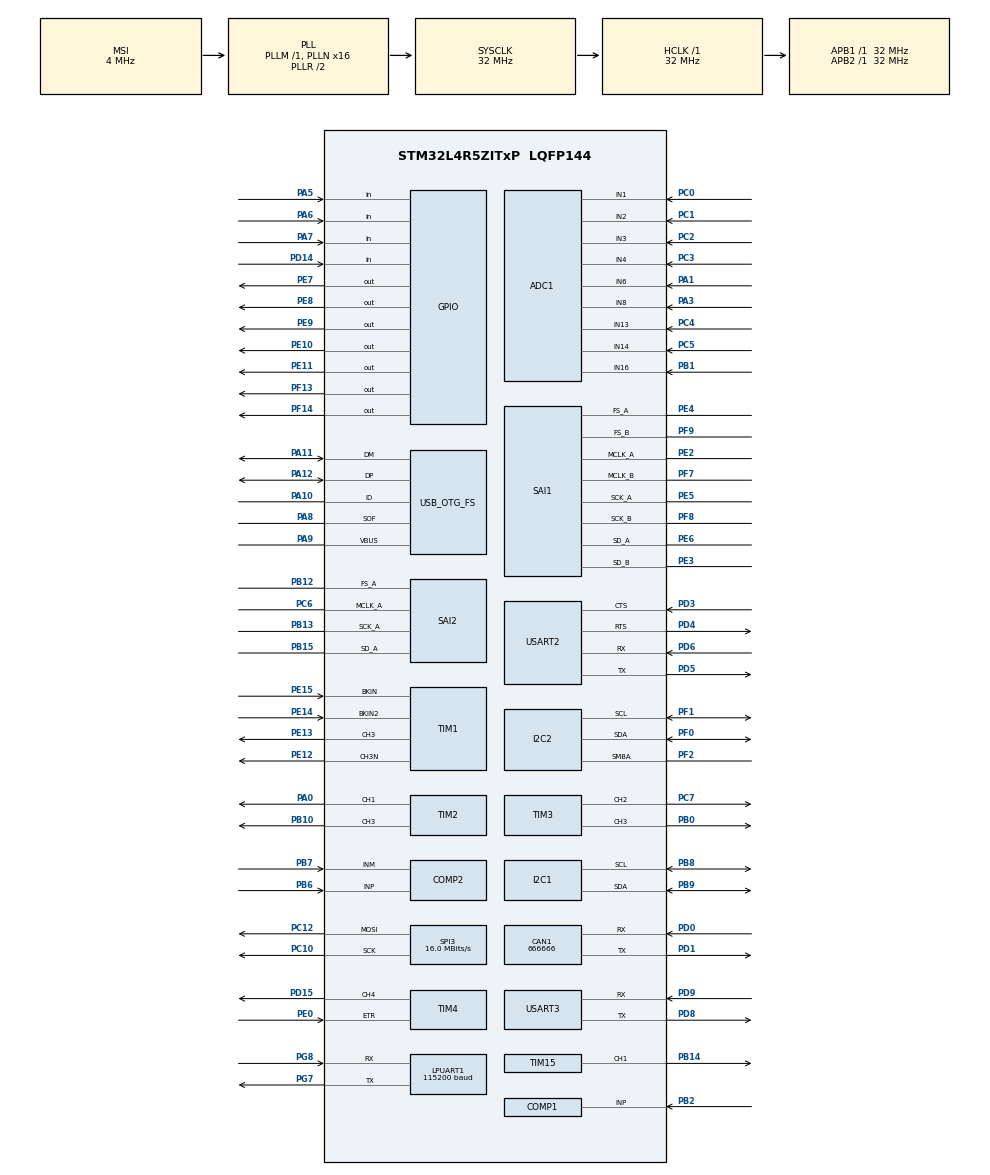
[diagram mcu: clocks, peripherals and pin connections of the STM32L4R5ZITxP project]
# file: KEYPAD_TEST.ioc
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ADC1.Channel-0\#ChannelRegularConversion=ADC_CHANNEL_1
ADC1.NbrOfConversionFlag=1
ADC1.OffsetNumber-0\#ChannelRegularConversion=ADC_OFFSET_NONE
ADC1.Rank-0\#ChannelRegularConversion=1
ADC1.SamplingTime-0\#ChannelRegularConversion=ADC_SAMPLETIME_2CYCLES_5
ADC1.master=1
CAN1.CalculateBaudRate=666666
CAN1.CalculateTimeBit=1500
CAN1.CalculateTimeQuantum=500.0
I2C1.Timeout=0x00008186
I2C1.Timing=0x00707CBB
I2C2.Timeout=0x00008186
I2C2.Timing=0x00707CBB
LPUART1.BaudRate=115200
LPUART1.WordLength=UART_WORDLENGTH_8B
Mcu.Family=STM32L4
Mcu.Name=STM32L4R5ZITxP
Mcu.Package=LQFP144
NVIC.PriorityGroup=NVIC_PRIORITYGROUP_4
PA0.Signal=S_TIM2_CH1
PA1.Signal=ADCx_IN6
PA10.Mode=OTG/Dual_Role_Device
PA10.Signal=USB_OTG_FS_ID
PA11.Mode=OTG/Dual_Role_Device
PA11.Signal=USB_OTG_FS_DM
PA12.Mode=OTG/Dual_Role_Device
PA12.Signal=USB_OTG_FS_DP
PA13\ (JTMS/SWDIO).Mode=Serial_Wire
PA13\ (JTMS/SWDIO).Signal=SYS_JTMS-SWDIO
PA14\ (JTCK/SWCLK).Mode=Serial_Wire
PA14\ (JTCK/SWCLK).Signal=SYS_JTCK-SWCLK
PA3.Signal=ADCx_IN8
PA4.Signal=SPI1_NSS
PA5.GPIO_PuPd=GPIO_PULLUP
PA5.Signal=GPIO_Input
PA6.GPIO_PuPd=GPIO_PULLUP
PA6.Signal=GPIO_Input
PA7.GPIO_PuPd=GPIO_PULLUP
PA7.Signal=GPIO_Input
PA8.Mode=Activate_SOF_FS
PA8.Signal=USB_OTG_FS_SOF
PA9.Mode=Activate_VBUS
PA9.Signal=USB_OTG_FS_VBUS
PB0.Signal=S_TIM3_CH3
PB1.Signal=ADCx_IN16
PB10.Signal=S_TIM2_CH3
PB12.Mode=SAI_A_MasterWithClock
PB12.Signal=SAI2_FS_A
PB13.Mode=SAI_A_MasterWithClock
PB13.Signal=SAI2_SCK_A
PB14.Signal=S_TIM15_CH1
PB15.Mode=SAI_A_MasterWithClock
PB15.Signal=SAI2_SD_A
PB2.Mode=INP
PB2.Signal=COMP1_INP
PB6.Mode=INP
PB6.Signal=COMP2_INP
PB7.Mode=INM
PB7.Signal=COMP2_INM
PB8.GPIO_Pu=GPIO_PULLUP
PB8.Mode=SMBus-two-wire-Interface
PB8.Signal=I2C1_SCL
PB9.GPIO_Pu=GPIO_PULLUP
PB9.Mode=SMBus-two-wire-Interface
PB9.Signal=I2C1_SDA
PC0.Signal=ADCx_IN1
PC1.Signal=ADCx_IN2
PC10.Mode=TX_Only_Simplex_Unidirect_Master
PC10.Signal=SPI3_SCK
PC11.Signal=SPI3_MISO
PC12.Mode=TX_Only_Simplex_Unidirect_Master
PC12.Signal=SPI3_MOSI
PC13.Mode=SYS_WakeUp1
PC13.Signal=SYS_WKUP2
PC14-OSC32_IN\ (PC14).Mode=LSE-External-Oscillator
PC14-OSC32_IN\ (PC14).Signal=RCC_OSC32_IN
PC15-OSC32_OUT\ (PC15).Mode=LSE-External-Oscillator
PC15-OSC32_OUT\ (PC15).Signal=RCC_OSC32_OUT
PC2.Signal=ADCx_IN3
PC3.Signal=ADCx_IN4
PC4.Signal=ADCx_IN13
PC5.Signal=ADCx_IN14
PC6.Mode=SAI_A_MasterWithClock
PC6.Signal=SAI2_MCLK_A
PC7.Signal=S_TIM3_CH2
PC8.Signal=SDMMC1_D0
PC9.Signal=SDMMC1_D1
PD0.Mode=CAN_Activate
PD0.Signal=CAN1_RX
PD1.Mode=CAN_Activate
PD1.Signal=CAN1_TX
PD14.GPIO_PuPd=GPIO_PULLUP
PD14.Signal=GPIO_Input
PD15.Signal=S_TIM4_CH4
PD2.Signal=SDMMC1_CMD
PD3.Mode=CTS_RTS
PD3.Signal=USART2_CTS
PD4.Mode=CTS_RTS
PD4.Signal=USART2_RTS
PD5.Mode=Asynchronous
PD5.Signal=USART2_TX
PD6.Mode=Asynchronous
PD6.Signal=USART2_RX
PD8.Mode=Asynchronous
PD8.Signal=USART3_TX
PD9.Mode=Asynchronous
PD9.Signal=USART3_RX
PE0.Signal=S_TIM4_ETR
PE10.GPIO_PuPd=GPIO_PULLUP
PE10.Signal=GPIO_Output
PE11.GPIO_ModeDefaultOutputPP=GPIO_MODE_OUTPUT_OD
PE11.GPIO_PuPd=GPIO_NOPULL
PE11.PinState=GPIO_PIN_RESET
PE11.Signal=GPIO_Output
PE12.Mode=PWM Generation3 CH3 CH3N
PE12.Signal=TIM1_CH3N
PE13.Signal=S_TIM1_CH3
PE14.Mode=Activate-Break-Input-2
PE14.Signal=TIM1_BKIN2
PE15.Mode=Activate-Break-Input
PE15.Signal=TIM1_BKIN
PE2.Mode=SAI_A_MasterWithClock
PE2.Signal=SAI1_MCLK_A
PE3.Mode=SAI_B_MasterWithClock
PE3.Signal=SAI1_SD_B
PE4.Mode=SAI_A_MasterWithClock
PE4.Signal=SAI1_FS_A
PE5.Mode=SAI_A_MasterWithClock
PE5.Signal=SAI1_SCK_A
PE6.Mode=SAI_A_MasterWithClock
PE6.Signal=SAI1_SD_A
PE7.GPIO_PuPd=GPIO_PULLUP
PE7.Signal=GPIO_Output
PE8.GPIO_PuPd=GPIO_PULLUP
PE8.Signal=GPIO_Output
PE9.GPIO_ModeDefaultOutputPP=GPIO_MODE_OUTPUT_OD
PE9.GPIO_PuPd=GPIO_NOPULL
PE9.PinState=GPIO_PIN_RESET
PE9.Signal=GPIO_Output
PF0.GPIO_Pu=GPIO_PULLUP
PF0.Mode=SMBus-Alert-mode
PF0.Signal=I2C2_SDA
PF1.GPIO_Pu=GPIO_PULLUP
PF1.Mode=SMBus-Alert-mode
PF1.Signal=I2C2_SCL
PF13.GPIO_ModeDefaultOutputPP=GPIO_MODE_OUTPUT_OD
PF13.GPIO_PuPd=GPIO_NOPULL
PF13.PinState=GPIO_PIN_RESET
PF13.Signal=GPIO_Output
PF14.GPIO_ModeDefaultOutputPP=GPIO_MODE_OUTPUT_OD
PF14.GPIO_PuPd=GPIO_NOPULL
PF14.PinState=GPIO_PIN_RESET
PF14.Signal=GPIO_Output
PF2.GPIO_Pu=GPIO_PULLUP
PF2.Mode=SMBus-Alert-mode
PF2.Signal=I2C2_SMBA
PF7.Mode=SAI_B_MasterWithClock
PF7.Signal=SAI1_MCLK_B
PF8.Mode=SAI_B_MasterWithClock
PF8.Signal=SAI1_SCK_B
PF9.Mode=SAI_B_MasterWithClock
PF9.Signal=SAI1_FS_B
PG7.Mode=Asynchronous
PG7.Signal=LPUART1_TX
PG8.Mode=Asynchronous
PG8.Signal=LPUART1_RX
PH0-OSC_IN\ (PH0).Mode=HSE-External-Oscillator
PH0-OSC_IN\ (PH0).Signal=RCC_OSC_IN
PH1-OSC_OUT\ (PH1).Mode=HSE-External-Oscillator
PH1-OSC_OUT\ (PH1).Signal=RCC_OSC_OUT
ProjectManager.HeapSize=0x200
ProjectManager.StackSize=0x400
ProjectManager.TargetToolchain=STM32CubeIDE
RCC.ADCFreq_Value=48000000
RCC.AHBFreq_Value=32000000
RCC.APB1Freq_Value=32000000
RCC.APB1TimFreq_Value=32000000
RCC.APB2Freq_Value=32000000
RCC.APB2TimFreq_Value=32000000
RCC.CortexFreq_Value=32000000
RCC.HCLKFreq_Value=32000000
RCC.HSE_VALUE=8000000
RCC.HSI48_VALUE=48000000
RCC.HSI_VALUE=16000000
RCC.MSI_VALUE=4000000
RCC.PLLN=16
RCC.PLLSAI1N=24
RCC.SYSCLKFreq_VALUE=32000000
RCC.SYSCLKSource=RCC_SYSCLKSOURCE_PLLCLK
RCC.USBFreq_Value=48000000
RCC.VCOOutputFreq_Value=64000000
SAI1.InitProtocol-SAI_A_MasterWithClock=Enable
SAI1.Instance-SAI_A_MasterWithClock=SAI$Index_Block_A
SAI1.Instance-SAI_B_MasterWithClock=SAI$Index_Block_B
SAI1.MClockEnable-SAI_A_MasterWithClock=SAI_MASTERCLOCK_ENABLE
SAI1.MClockEnable-SAI_B_MasterWithClock=SAI_MASTERCLOCK_ENABLE
SAI1.Synchro-SAI_A_MasterWithClock=SAI_ASYNCHRONOUS
SAI1.Synchro-SAI_B_MasterWithClock=SAI_ASYNCHRONOUS
SAI1.VirtualMode-SAI_A_MasterWithClock=VM_MASTER
SAI1.VirtualMode-SAI_B_MasterWithClock=VM_MASTER
SAI1.VirtualProtocol-SAI_A_BASIC=VM_BASIC_PROTOCOL
SAI2.Instance-SAI_A_MasterWithClock=SAI$Index_Block_A
SAI2.MClockEnable-SAI_A_MasterWithClock=SAI_MASTERCLOCK_ENABLE
SAI2.Synchro-SAI_A_MasterWithClock=SAI_ASYNCHRONOUS
SAI2.VirtualMode-SAI_A_MasterWithClock=VM_MASTER
SH.ADCx_IN1.0=ADC1_IN1,IN1-Single-Ended
SH.ADCx_IN13.0=ADC1_IN13,IN13-Single-Ended
SH.ADCx_IN14.0=ADC1_IN14,IN14-Single-Ended
SH.ADCx_IN16.0=ADC1_IN16,IN16-Single-Ended
SH.ADCx_IN2.0=ADC1_IN2,IN2-Single-Ended
SH.ADCx_IN3.0=ADC1_IN3,IN3-Single-Ended
SH.ADCx_IN4.0=ADC1_IN4,IN4-Single-Ended
SH.ADCx_IN6.0=ADC1_IN6,IN6-Single-Ended
SH.ADCx_IN8.0=ADC1_IN8,IN8-Single-Ended
SH.S_TIM15_CH1.0=TIM15_CH1,PWM Generation1 CH1
SH.S_TIM1_CH3.0=TIM1_CH3,PWM Generation3 CH3 CH3N
SH.S_TIM2_CH1.0=TIM2_CH1,PWM Generation1 CH1
SH.S_TIM2_CH3.0=TIM2_CH3,PWM Generation3 CH3
SH.S_TIM3_CH2.0=TIM3_CH2,PWM Generation2 CH2
SH.S_TIM3_CH3.0=TIM3_CH3,PWM Generation3 CH3
SH.S_TIM4_CH4.0=TIM4_CH4,PWM Generation4 CH4
SH.S_TIM4_ETR.0=TIM4_ETR,ETR-as-clearing-source
SPI3.CalculateBaudRate=16.0 MBits/s
SPI3.DataSize=SPI_DATASIZE_8BIT
SPI3.Direction=SPI_DIRECTION_2LINES
SPI3.Mode=SPI_MODE_MASTER
SPI3.VirtualType=VM_MASTER
TIM1.Channel-PWM\ Generation3\ CH3\ CH3N=TIM_CHANNEL_3
TIM15.Channel-PWM\ Generation1\ CH1=TIM_CHANNEL_1
TIM2.Channel-PWM\ Generation1\ CH1=TIM_CHANNEL_1
TIM2.Channel-PWM\ Generation3\ CH3=TIM_CHANNEL_3
TIM3.Channel-PWM\ Generation2\ CH2=TIM_CHANNEL_2
TIM3.Channel-PWM\ Generation3\ CH3=TIM_CHANNEL_3
TIM4.Channel-PWM\ Generation4\ CH4=TIM_CHANNEL_4
USART2.VirtualMode-Asynchronous=VM_ASYNC
USART3.VirtualMode-Asynchronous=VM_ASYNC
VP_COMP1_VS_VREFINT.Mode=VREFINT
VP_SAI1_VP_$IpInstance_SAIA_SAI_BASIC.Mode=SAI_A_BASIC
board=NUCLEO-L4R5ZI-P

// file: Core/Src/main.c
/* USER CODE BEGIN Header */
/**
 ******************************************************************************
 * @file           : main.c
 * @brief          : Main program body
 ******************************************************************************
 * @attention
 *
 * Copyright (c) 2024 STMicroelectronics.
 * All rights reserved.
 *
 * This software is licensed under terms that can be found in the LICENSE file
 * in the root directory of this software component.
 * If no LICENSE file comes with this software, it is provided AS-IS.
 *
 ******************************************************************************
 */
/* USER CODE END Header */
#include "main.h"

ADC_HandleTypeDef hadc1;

CAN_HandleTypeDef hcan1;

COMP_HandleTypeDef hcomp1;
COMP_HandleTypeDef hcomp2;

SMBUS_HandleTypeDef hsmbus1;
SMBUS_HandleTypeDef hsmbus2;

UART_HandleTypeDef hlpuart1;
UART_HandleTypeDef huart2;
UART_HandleTypeDef huart3;

SAI_HandleTypeDef hsai_BlockB1;
SAI_HandleTypeDef hsai_BlockA1;
SAI_HandleTypeDef hsai_BlockA2;

SPI_HandleTypeDef hspi3;

TIM_HandleTypeDef htim1;
TIM_HandleTypeDef htim2;
TIM_HandleTypeDef htim3;
TIM_HandleTypeDef htim4;
TIM_HandleTypeDef htim15;

/* USER CODE BEGIN PV */
// Defining dimensions of LCD display
#define LCD_WIDTH 240
#define LCD_HEIGHT 320

// Commands to control SPI display
// Specifically the ST7789 driver
typedef enum {
  CMD_MADCTL_MY = 0x80,
  CMD_MADCTL_MX = 0x40,
  CMD_MADCTL_MV = 0x20,
  CMD_MADCTL_ML = 0x10,
  CMD_MADCTL_RGB = 0x00,
  CMD_MADCTL_BGR = 0x08,
  CMD_MADCTL_MH = 0x04,
  CMD_NOP = 0x00,
  CMD_SWRESET = 0x01,
  CMD_RDDID = 0x04,
  CMD_RDDST = 0x09,
  CMD_SLPIN = 0x10,
  CMD_SLPOUT = 0x11,
  CMD_PTLON = 0x12,
  CMD_NORON = 0x13,
  CMD_INVOFF = 0x20,
  CMD_INVON = 0x21,
  CMD_GAMSET = 0x26,
  CMD_DISPOFF = 0x28,
  CMD_DISPON = 0x29,
  CMD_CASET = 0x2A,
  CMD_RASET = 0x2B,
  CMD_RAMWR = 0x2C,
  CMD_RAMRD = 0x2E,
  CMD_PTLAR = 0x30,
  CMD_MADCTL = 0x36,
  CMD_IDMOFF = 0x38,
  CMD_IDMON = 0x39,
  CMD_COLMOD = 0x3A,
  CMD_RAMCTRL = 0xB0,
  CMD_FRMCTR1 = 0xB1,
  CMD_RGBCTRL = 0xB1,
  CMD_FRMCTR2 = 0xB2,
  CMD_PORCTRL = 0xB2,
  CMD_FRMCTR3 = 0xB3,
  CMD_FRCTRL1 = 0xB3,
  CMD_INVCTR = 0xB4,
  CMD_PARCTRL = 0xB5,
  CMD_DISSET5 = 0xB6,
  CMD_GCTRL = 0xB7,
  CMD_VCOMS = 0xBB,
  CMD_PWCTR1 = 0xC0,
  CMD_LCMCTRL = 0xC0,
  CMD_PWCTR2 = 0xC1,
  CMD_IDSET = 0xC1,
  CMD_PWCTR3 = 0xC2,
  CMD_VDVVRHEN = 0xC2,
  CMD_PWCTR4 = 0xC3,
  CMD_VRHS = 0xC3,
  CMD_PWCTR5 = 0xC4,
  CMD_VDVS = 0xC4,
  CMD_VMCTR1 = 0xC5,
  CMD_VCMOFSET = 0xC5,
  CMD_FRCTRL2 = 0xC6,
  CMD_PWCTRL1 = 0xD0,
  CMD_RDID1 = 0xDA,
  CMD_RDID2 = 0xDB,
  CMD_RDID3 = 0xDC,
  CMD_RDID4 = 0xDD,
  CMD_PWCTR6 = 0xFC,
  CMD_GMCTRP1 = 0xE0,
  CMD_GMCTRN1 = 0xE1,
  CMD_COLOR_MODE_16bit = 0x55,
  CMD_COLOR_MODE_18bit = 0x66,
} lcd_cmds;

// I'm still not sure how this defines rotation TBH
#define LCD_ROTATION_CMD (CMD_MADCTL_MX | CMD_MADCTL_MY | CMD_MADCTL_RGB)

// Commands to be run during initialization
const uint8_t init_cmd[] = {
    0,  CMD_SLPOUT,
    1,  CMD_COLMOD,  CMD_COLOR_MODE_16bit,
    5,  CMD_PORCTRL, 0x0C, 0x0C, 0x00, 0x33, 0x33,   // Standard porch
  //5,  CMD_PORCTRL, 0x01, 0x01, 0x00, 0x11, 0x11,   // Minimum porch (7% faster screen refresh rate)
    1,  CMD_GCTRL,   0x35,                           // Gate Control, Default value
    1,  CMD_VCOMS,   0x19,                           // VCOM setting 0.725v (default 0.75v for 0x20)
    1,  CMD_LCMCTRL, 0X2C,                           // LCMCTRL, Default value
    1,  CMD_VDVVRHEN,0x01,                           // VDV and VRH command Enable, Default value
    1,  CMD_VRHS,    0x12,                           // VRH set, +-4.45v (default +-4.1v for 0x0B)
    1,  CMD_VDVS,    0x20,                           // VDV set, Default value
    1,  CMD_FRCTRL2, 0x0F,                           // Frame rate control in normal mode, Default refresh rate (60Hz)
  //1,  CMD_FRCTRL2, 0x01,                           // Frame rate control in normal mode, Max refresh rate (111Hz)
    2,  CMD_PWCTRL1, 0xA4, 0xA1,
    1,  CMD_MADCTL,  LCD_ROTATION_CMD,
    14, CMD_GMCTRP1, 0xD0, 0x04, 0x0D, 0x11, 0x13, 0x2B, 0x3F, 0x54, 0x4C, 0x18, 0x0D, 0x0B, 0x1F, 0x23,
    14, CMD_GMCTRN1, 0xD0, 0x04, 0x0C, 0x11, 0x13, 0x2C, 0x3F, 0x44, 0x51, 0x2F, 0x1F, 0x1F, 0x20, 0x23,
    0,  CMD_INVON,
    0,  CMD_NORON
};

/* USER CODE END PV */

void SystemClock_Config(void);
void PeriphCommonClock_Config(void);
static void MX_GPIO_Init(void);
static void MX_ADC1_Init(void);
static void MX_CAN1_Init(void);
static void MX_COMP1_Init(void);
static void MX_COMP2_Init(void);
static void MX_I2C1_SMBUS_Init(void);
static void MX_I2C2_SMBUS_Init(void);
static void MX_LPUART1_UART_Init(void);
static void MX_USART2_UART_Init(void);
static void MX_USART3_UART_Init(void);
static void MX_SAI1_Init(void);
static void MX_SAI2_Init(void);
static void MX_SPI3_Init(void);
static void MX_TIM1_Init(void);
static void MX_TIM2_Init(void);
static void MX_TIM3_Init(void);
static void MX_TIM4_Init(void);
static void MX_TIM15_Init(void);
static void MX_USB_OTG_FS_USB_Init(void);

/* USER CODE BEGIN 0 */
// #define SPI3_ADDR 0x40003C00
// #define SPI_CR1_OFFSET 0x00
// #define SPI_CR2_OFFSET 0x04

// Send a command to the display
static void LCD_WriteCommand(uint8_t *cmd, uint8_t argc) {
  //    setSPI_Size(mode_8bit);
  //    LCD_PIN(LCD_DC,RESET);
  HAL_GPIO_WritePin(GPIOE, GPIO_PIN_8, 0);   // DC
  HAL_GPIO_WritePin(GPIOE, GPIO_PIN_10, 0);  // CS

  HAL_SPI_Transmit(&hspi3, cmd, 1, HAL_MAX_DELAY);
  if (argc) {
    HAL_GPIO_WritePin(GPIOE, GPIO_PIN_8, 1);
    HAL_SPI_Transmit(&hspi3, (cmd + 1), argc, HAL_MAX_DELAY);
  }
  HAL_GPIO_WritePin(GPIOE, GPIO_PIN_10, 1);  // CS
}

// Power on display
void LCD_setPower(uint8_t power) {
  uint8_t cmd[] = {(power ? CMD_DISPON /* TEON */ : CMD_DISPOFF /* TEOFF */)};
  LCD_WriteCommand(cmd, sizeof(cmd) - 1);
}

// Initialize display
void LCD_init(void) {
  HAL_GPIO_WritePin(GPIOE, GPIO_PIN_10, 1);  // CS
  HAL_GPIO_WritePin(GPIOE, GPIO_PIN_7, 0);   // RST
  HAL_Delay(1);
  HAL_GPIO_WritePin(GPIOE, GPIO_PIN_7, 1);  // RST
  HAL_Delay(200);
  // Iterate through initialization commands defined previousy
  for (uint16_t i = 0; i < sizeof(init_cmd);) {
    LCD_WriteCommand((uint8_t *)&init_cmd[i + 1], init_cmd[i]);
    i += init_cmd[i] + 2;
  }
  // Power on display once initialized
  LCD_setPower(ENABLE);
}

static void LCD_SetAddressWindow(int16_t x0, int16_t y0, int16_t x1,
                                 int16_t y1) {
  int16_t x_start = x0 /*+ LCD_X_SHIFT*/, x_end = x1 /*+ LCD_X_SHIFT*/;
  int16_t y_start = y0 /*+ LCD_Y_SHIFT*/, y_end = y1 /*+ LCD_Y_SHIFT*/;

  /* Column Address set */
  {
    uint8_t cmd[] = {CMD_CASET, x_start >> 8, x_start & 0xFF, x_end >> 8,
                     x_end & 0xFF};
    LCD_WriteCommand(cmd, sizeof(cmd) - 1);
  }
  /* Row Address set */
  {
    uint8_t cmd[] = {CMD_RASET, y_start >> 8, y_start & 0xFF, y_end >> 8,
                     y_end & 0xFF};
    LCD_WriteCommand(cmd, sizeof(cmd) - 1);
  }
  {
    /* Write to RAM */
    uint8_t cmd[] = {CMD_RAMWR};
    LCD_WriteCommand(cmd, sizeof(cmd) - 1);
  }
}

void LCD_DrawPixel(int16_t x, int16_t y, uint16_t color) {
  if ((x < 0) || (x > LCD_WIDTH - 1) || (y < 0) || (y > LCD_HEIGHT - 1)) return;

  uint8_t data[2] = {color >> 8, color & 0xFF};

  LCD_SetAddressWindow(x, y, x, y);

  HAL_GPIO_WritePin(GPIOE, GPIO_PIN_8, 1);  // DC

  HAL_GPIO_WritePin(GPIOE, GPIO_PIN_10, 0);  // CS

  HAL_SPI_Transmit(&hspi3, data, sizeof(data), HAL_MAX_DELAY);
  HAL_GPIO_WritePin(GPIOE, GPIO_PIN_10, 1);  // CS
}

/* USER CODE END 0 */

int main(void) {
  /* USER CODE BEGIN 1 */

  // SPI3 address 0x40003C00
  // SPI3_CR1 offset is 0x00
  // SPI3_CR2 offset is 0x04

  /* USER CODE END 1 */

  /* MCU Configuration--------------------------------------------------------*/

  /* Reset of all peripherals, Initializes the Flash interface and the Systick.
   */
  HAL_Init();

  /* Configure the system clock */
  SystemClock_Config();

  /* Configure the peripherals common clocks */
  PeriphCommonClock_Config();

  /* Initialize all configured peripherals */
  MX_GPIO_Init();
  MX_ADC1_Init();
  MX_CAN1_Init();
  MX_COMP1_Init();
  MX_COMP2_Init();
  MX_I2C1_SMBUS_Init();
  MX_I2C2_SMBUS_Init();
  MX_LPUART1_UART_Init();
  MX_USART2_UART_Init();
  MX_USART3_UART_Init();
  MX_SAI1_Init();
  MX_SAI2_Init();
  MX_SPI3_Init();
  MX_TIM1_Init();
  MX_TIM2_Init();
  MX_TIM3_Init();
  MX_TIM4_Init();
  MX_TIM15_Init();
  MX_USB_OTG_FS_USB_Init();
  /* USER CODE BEGIN 2 */

  //  struct ROW_RETURN{
  //	  int row1;
  //	  int row2;
  //	  int row3;
  //	  int row4;
  //  };

  /**
   * KEYPAD FUNCTIONS BELOW
  */
  int RowChecker() {
    // struct ROW_RETURN row_return;

    //	  	row_return.row1 = HAL_GPIO_ReadPin(GPIOA, GPIO_PIN_5) ==
    // GPIO_PIN_RESET; 	  	row_return.row2 =  HAL_GPIO_ReadPin(GPIOA,
    // GPIO_PIN_6) == GPIO_PIN_RESET; 	  	row_return.row3 =
    // HAL_GPIO_ReadPin(GPIOA, GPIO_PIN_7) == GPIO_PIN_RESET;
    // row_return.row4 = HAL_GPIO_ReadPin(GPIOD, GPIO_PIN_14) == GPIO_PIN_RESET;
    int val = 0;
    val = HAL_GPIO_ReadPin(GPIOA, GPIO_PIN_5) == GPIO_PIN_RESET ? 1 : val;
    val = HAL_GPIO_ReadPin(GPIOA, GPIO_PIN_6) == GPIO_PIN_RESET ? 2 : val;
    val = HAL_GPIO_ReadPin(GPIOA, GPIO_PIN_7) == GPIO_PIN_RESET ? 3 : val;
    val = HAL_GPIO_ReadPin(GPIOD, GPIO_PIN_14) == GPIO_PIN_RESET ? 4 : val;
    //	  	return row_return;
    return val;
  }

  //  struct ROW_RETURN Col1_Return;
  //  struct ROW_RETURN Col2_Return;
  //  struct ROW_RETURN Col3_Return;
  //  struct ROW_RETURN Col4_Return;
  int val = 0;
  HAL_GPIO_WritePin(GPIOE, GPIO_PIN_9, 1);
  HAL_GPIO_WritePin(GPIOF, GPIO_PIN_13, 1);
  HAL_GPIO_WritePin(GPIOE, GPIO_PIN_11, 1);
  HAL_GPIO_WritePin(GPIOF, GPIO_PIN_14, 1);
  uint8_t ASCII_Keypad_Lookup[4][4] = {{0x31, 0x32, 0x33, 0x41},
                                       {0x34, 0x35, 0x36, 0x42},
                                       {0x37, 0x38, 0x39, 0x43},
                                       {0x2A, 0x30, 0x23, 0x44}};
  const uint8_t max_digits = 5;
  uint8_t ASCII_Weight[max_digits];
  uint8_t weightCounter = 0;
  // uint8_t ASCII_Height [5];
  // uint8_t heightCounter = 0; implement later

  void KeyPadReturn(int row, int col) {
    if (row == 0) {
      return;
    }
    HAL_Delay(10);
    while (row == RowChecker()) {
    }
    HAL_Delay(10);
    uint8_t ASCII_Value = ASCII_Keypad_Lookup[row - 1][col - 1];
    // Check if '#' is pressed
    if (ASCII_Value == 0x23) {
      if (weightCounter == 0) {
        // If there is no value for weight, just return
        return;
      }
      // print the weight or height
      printf("End ASCII value: ");
      for (uint8_t i = 0; i < weightCounter; i++) {
        // print the values here
        printf("%x ", ASCII_Weight[i]);
      }
      printf("\n");
      weightCounter = 0;
      return;
    } else if (ASCII_Value == 0x2A || weightCounter == max_digits - 2) {
      // Reset if '*' is the input
      // Other if statement:
      // -2: there is a ++ at the end, and need a spot for #
      // Reset if max digits have been reached
      weightCounter = 0;
      return;
    }
    printf("ASCII value: %x\n", ASCII_Value);
    ASCII_Weight[weightCounter] = ASCII_Value;
    weightCounter++;
  }

  /**
   * DISPLAY FUNCTIONS BELOW
  */
  LCD_init();

  //  uint8_t data[2] = {0xffc0 >> 8, 0xffc0 & 0xFF};
  //
  //  uint8_t cmd[] = { CMD_CASET, 50 >> 8, 50 & 0xFF, 50 >> 8, 50 & 0xFF };
  //  HAL_SPI_Transmit(&hspi3, cmd, 1, HAL_MAX_DELAY);
  //  HAL_SPI_Transmit(&hspi3, data, sizeof(data), HAL_MAX_DELAY);

  // LOOPS below draw the message "Hi"
  for (int i = 0; i < 240; i++) {
    for (int j = 0; j < 320; j++) {
      LCD_DrawPixel(i, j, 0x0149);
    }
  }

  for (int j = 120; j < 240; j++) {
    LCD_DrawPixel(200, j, 0xffC0);
    LCD_DrawPixel(201, j, 0xffC0);
    LCD_DrawPixel(202, j, 0xffC0);
    LCD_DrawPixel(203, j, 0xffC0);
    LCD_DrawPixel(204, j, 0xffC0);
    LCD_DrawPixel(205, j, 0xffC0);
  }

  for (int j = 120; j < 240; j++) {
    LCD_DrawPixel(140, j, 0xffC0);
    LCD_DrawPixel(141, j, 0xffC0);
    LCD_DrawPixel(142, j, 0xffC0);
    LCD_DrawPixel(143, j, 0xffC0);
    LCD_DrawPixel(144, j, 0xffC0);
    LCD_DrawPixel(145, j, 0xffC0);
  }
  for (int i = 205; i > 144; i--) {
    LCD_DrawPixel(i, 180, 0xffC0);
    LCD_DrawPixel(i, 181, 0xffC0);
    LCD_DrawPixel(i, 182, 0xffC0);
    LCD_DrawPixel(i, 183, 0xffC0);
    LCD_DrawPixel(i, 184, 0xffC0);
    LCD_DrawPixel(i, 185, 0xffC0);
  }
  for (int j = 120; j < 200; j++) {
    LCD_DrawPixel(120, j, 0xffC0);
    LCD_DrawPixel(121, j, 0xffC0);
    LCD_DrawPixel(122, j, 0xffC0);
    LCD_DrawPixel(123, j, 0xffC0);
    LCD_DrawPixel(124, j, 0xffC0);
    LCD_DrawPixel(125, j, 0xffC0);
  }
  for (int j = 220; j < 226; j++) {
    LCD_DrawPixel(120, j, 0xffC0);
    LCD_DrawPixel(121, j, 0xffC0);
    LCD_DrawPixel(122, j, 0xffC0);
    LCD_DrawPixel(123, j, 0xffC0);
    LCD_DrawPixel(124, j, 0xffC0);
    LCD_DrawPixel(125, j, 0xffC0);
  }
  // End of "Hi" message

  /* USER CODE END 2 */

  /* Infinite loop */
  /* USER CODE BEGIN WHILE */
  while (1) {
    //	  LCD_DrawPixel(50, 50, 0x001f);
    //	  LCD_DrawPixel(100, 100, 0xffC0);
    //	  LCD_DrawPixel(100, 100, 0x001f);
    //	  LCD_DrawPixel(1, 1, 0xffC0);
    //	  LCD_DrawPixel(1, 1, 0x001f);
    HAL_Delay(500);
    // COMMENTING BELOW FOR DISPLAY TESTING
    //    HAL_GPIO_WritePin(GPIOF, GPIO_PIN_13, 0);
    //    val = RowChecker();
    //    KeyPadReturn(val, 4);
    //    HAL_GPIO_WritePin(GPIOF, GPIO_PIN_13, 1);
    //
    //    HAL_GPIO_WritePin(GPIOE, GPIO_PIN_9, 0);
    //    val = RowChecker();
    //    KeyPadReturn(val, 3);
    //    HAL_GPIO_WritePin(GPIOE, GPIO_PIN_9, 1);
    //
    //    HAL_GPIO_WritePin(GPIOE, GPIO_PIN_11, 0);
    //    val = RowChecker();
    //    KeyPadReturn(val, 2);
    //    HAL_GPIO_WritePin(GPIOE, GPIO_PIN_11, 1);
    //
    //    HAL_GPIO_WritePin(GPIOF, GPIO_PIN_14, 0);
    //    val = RowChecker();
    //    KeyPadReturn(val, 1);
    //    HAL_GPIO_WritePin(GPIOF, GPIO_PIN_14, 1);

    /* USER CODE END WHILE */

  }
}

void SystemClock_Config(void) {
  RCC_OscInitTypeDef RCC_OscInitStruct = {0};
  RCC_ClkInitTypeDef RCC_ClkInitStruct = {0};

  /** Configure the main internal regulator output voltage
   */
  if (HAL_PWREx_ControlVoltageScaling(PWR_REGULATOR_VOLTAGE_SCALE1) != HAL_OK) {
    Error_Handler();
  }

  /** Configure LSE Drive Capability
   */
  HAL_PWR_EnableBkUpAccess();
  __HAL_RCC_LSEDRIVE_CONFIG(RCC_LSEDRIVE_LOW);

  /** Initializes the RCC Oscillators according to the specified parameters
   * in the RCC_OscInitTypeDef structure.
   */
  RCC_OscInitStruct.OscillatorType =
      RCC_OSCILLATORTYPE_LSE | RCC_OSCILLATORTYPE_MSI;
  RCC_OscInitStruct.LSEState = RCC_LSE_ON;
  RCC_OscInitStruct.MSIState = RCC_MSI_ON;
  RCC_OscInitStruct.MSICalibrationValue = 0;
  RCC_OscInitStruct.MSIClockRange = RCC_MSIRANGE_6;
  RCC_OscInitStruct.PLL.PLLState = RCC_PLL_ON;
  RCC_OscInitStruct.PLL.PLLSource = RCC_PLLSOURCE_MSI;
  RCC_OscInitStruct.PLL.PLLM = 1;
  RCC_OscInitStruct.PLL.PLLN = 16;
  RCC_OscInitStruct.PLL.PLLP = RCC_PLLP_DIV2;
  RCC_OscInitStruct.PLL.PLLQ = RCC_PLLQ_DIV2;
  RCC_OscInitStruct.PLL.PLLR = RCC_PLLR_DIV2;
  if (HAL_RCC_OscConfig(&RCC_OscInitStruct) != HAL_OK) {
    Error_Handler();
  }

  /** Initializes the CPU, AHB and APB buses clocks
   */
  RCC_ClkInitStruct.ClockType = RCC_CLOCKTYPE_HCLK | RCC_CLOCKTYPE_SYSCLK |
                                RCC_CLOCKTYPE_PCLK1 | RCC_CLOCKTYPE_PCLK2;
  RCC_ClkInitStruct.SYSCLKSource = RCC_SYSCLKSOURCE_PLLCLK;
  RCC_ClkInitStruct.AHBCLKDivider = RCC_SYSCLK_DIV1;
  RCC_ClkInitStruct.APB1CLKDivider = RCC_HCLK_DIV1;
  RCC_ClkInitStruct.APB2CLKDivider = RCC_HCLK_DIV1;

  if (HAL_RCC_ClockConfig(&RCC_ClkInitStruct, FLASH_LATENCY_1) != HAL_OK) {
    Error_Handler();
  }

  /** Enable MSI Auto calibration
   */
  HAL_RCCEx_EnableMSIPLLMode();
}

void PeriphCommonClock_Config(void) {
  RCC_PeriphCLKInitTypeDef PeriphClkInit = {0};

  /** Initializes the peripherals clock
   */
  PeriphClkInit.PeriphClockSelection = RCC_PERIPHCLK_SAI1 | RCC_PERIPHCLK_SAI2 |
                                       RCC_PERIPHCLK_USB | RCC_PERIPHCLK_ADC;
  PeriphClkInit.Sai1ClockSelection = RCC_SAI1CLKSOURCE_PLLSAI1;
  PeriphClkInit.Sai2ClockSelection = RCC_SAI2CLKSOURCE_PLLSAI1;
  PeriphClkInit.AdcClockSelection = RCC_ADCCLKSOURCE_PLLSAI1;
  PeriphClkInit.UsbClockSelection = RCC_USBCLKSOURCE_PLLSAI1;
  PeriphClkInit.PLLSAI1.PLLSAI1Source = RCC_PLLSOURCE_MSI;
  PeriphClkInit.PLLSAI1.PLLSAI1M = 1;
  PeriphClkInit.PLLSAI1.PLLSAI1N = 24;
  PeriphClkInit.PLLSAI1.PLLSAI1P = RCC_PLLP_DIV2;
  PeriphClkInit.PLLSAI1.PLLSAI1Q = RCC_PLLQ_DIV2;
  PeriphClkInit.PLLSAI1.PLLSAI1R = RCC_PLLR_DIV2;
  PeriphClkInit.PLLSAI1.PLLSAI1ClockOut =
      RCC_PLLSAI1_SAI1CLK | RCC_PLLSAI1_48M2CLK | RCC_PLLSAI1_ADC1CLK;
  if (HAL_RCCEx_PeriphCLKConfig(&PeriphClkInit) != HAL_OK) {
    Error_Handler();
  }
}

static void MX_ADC1_Init(void) {

  ADC_ChannelConfTypeDef sConfig = {0};

  /** Common config
   */
  hadc1.Instance = ADC1;
  hadc1.Init.ClockPrescaler = ADC_CLOCK_ASYNC_DIV1;
  hadc1.Init.Resolution = ADC_RESOLUTION_12B;
  hadc1.Init.DataAlign = ADC_DATAALIGN_RIGHT;
  hadc1.Init.ScanConvMode = ADC_SCAN_DISABLE;
  hadc1.Init.EOCSelection = ADC_EOC_SINGLE_CONV;
  hadc1.Init.LowPowerAutoWait = DISABLE;
  hadc1.Init.ContinuousConvMode = DISABLE;
  hadc1.Init.NbrOfConversion = 1;
  hadc1.Init.DiscontinuousConvMode = DISABLE;
  hadc1.Init.ExternalTrigConv = ADC_SOFTWARE_START;
  hadc1.Init.ExternalTrigConvEdge = ADC_EXTERNALTRIGCONVEDGE_NONE;
  hadc1.Init.DMAContinuousRequests = DISABLE;
  hadc1.Init.Overrun = ADC_OVR_DATA_PRESERVED;
  hadc1.Init.OversamplingMode = DISABLE;
  if (HAL_ADC_Init(&hadc1) != HAL_OK) {
    Error_Handler();
  }

  /** Configure Regular Channel
   */
  sConfig.Channel = ADC_CHANNEL_1;
  sConfig.Rank = ADC_REGULAR_RANK_1;
  sConfig.SamplingTime = ADC_SAMPLETIME_2CYCLES_5;
  sConfig.SingleDiff = ADC_SINGLE_ENDED;
  sConfig.OffsetNumber = ADC_OFFSET_NONE;
  sConfig.Offset = 0;
  if (HAL_ADC_ConfigChannel(&hadc1, &sConfig) != HAL_OK) {
    Error_Handler();
  }
}

static void MX_CAN1_Init(void) {

  hcan1.Instance = CAN1;
  hcan1.Init.Prescaler = 16;
  hcan1.Init.Mode = CAN_MODE_NORMAL;
  hcan1.Init.SyncJumpWidth = CAN_SJW_1TQ;
  hcan1.Init.TimeSeg1 = CAN_BS1_1TQ;
  hcan1.Init.TimeSeg2 = CAN_BS2_1TQ;
  hcan1.Init.TimeTriggeredMode = DISABLE;
  hcan1.Init.AutoBusOff = DISABLE;
  hcan1.Init.AutoWakeUp = DISABLE;
  hcan1.Init.AutoRetransmission = DISABLE;
  hcan1.Init.ReceiveFifoLocked = DISABLE;
  hcan1.Init.TransmitFifoPriority = DISABLE;
  if (HAL_CAN_Init(&hcan1) != HAL_OK) {
    Error_Handler();
  }
}

static void MX_COMP1_Init(void) {

  hcomp1.Instance = COMP1;
  hcomp1.Init.InvertingInput = COMP_INPUT_MINUS_VREFINT;
  hcomp1.Init.NonInvertingInput = COMP_INPUT_PLUS_IO2;
  hcomp1.Init.OutputPol = COMP_OUTPUTPOL_NONINVERTED;
  hcomp1.Init.Hysteresis = COMP_HYSTERESIS_NONE;
  hcomp1.Init.BlankingSrce = COMP_BLANKINGSRC_NONE;
  hcomp1.Init.Mode = COMP_POWERMODE_HIGHSPEED;
  hcomp1.Init.WindowMode = COMP_WINDOWMODE_DISABLE;
  hcomp1.Init.TriggerMode = COMP_TRIGGERMODE_NONE;
  if (HAL_COMP_Init(&hcomp1) != HAL_OK) {
    Error_Handler();
  }
}

static void MX_COMP2_Init(void) {

  hcomp2.Instance = COMP2;
  hcomp2.Init.InvertingInput = COMP_INPUT_MINUS_IO2;
  hcomp2.Init.NonInvertingInput = COMP_INPUT_PLUS_IO2;
  hcomp2.Init.OutputPol = COMP_OUTPUTPOL_NONINVERTED;
  hcomp2.Init.Hysteresis = COMP_HYSTERESIS_NONE;
  hcomp2.Init.BlankingSrce = COMP_BLANKINGSRC_NONE;
  hcomp2.Init.Mode = COMP_POWERMODE_HIGHSPEED;
  hcomp2.Init.WindowMode = COMP_WINDOWMODE_DISABLE;
  hcomp2.Init.TriggerMode = COMP_TRIGGERMODE_NONE;
  if (HAL_COMP_Init(&hcomp2) != HAL_OK) {
    Error_Handler();
  }
}

static void MX_I2C1_SMBUS_Init(void) {

  hsmbus1.Instance = I2C1;
  hsmbus1.Init.Timing = 0x00707CBB;
  hsmbus1.Init.AnalogFilter = SMBUS_ANALOGFILTER_ENABLE;
  hsmbus1.Init.OwnAddress1 = 2;
  hsmbus1.Init.AddressingMode = SMBUS_ADDRESSINGMODE_7BIT;
  hsmbus1.Init.DualAddressMode = SMBUS_DUALADDRESS_DISABLE;
  hsmbus1.Init.OwnAddress2 = 0;
  hsmbus1.Init.OwnAddress2Masks = SMBUS_OA2_NOMASK;
  hsmbus1.Init.GeneralCallMode = SMBUS_GENERALCALL_DISABLE;
  hsmbus1.Init.NoStretchMode = SMBUS_NOSTRETCH_DISABLE;
  hsmbus1.Init.PacketErrorCheckMode = SMBUS_PEC_DISABLE;
  hsmbus1.Init.PeripheralMode = SMBUS_PERIPHERAL_MODE_SMBUS_SLAVE;
  hsmbus1.Init.SMBusTimeout = 0x00008186;
  if (HAL_SMBUS_Init(&hsmbus1) != HAL_OK) {
    Error_Handler();
  }
}

static void MX_I2C2_SMBUS_Init(void) {

  hsmbus2.Instance = I2C2;
  hsmbus2.Init.Timing = 0x00707CBB;
  hsmbus2.Init.AnalogFilter = SMBUS_ANALOGFILTER_ENABLE;
  hsmbus2.Init.OwnAddress1 = 2;
  hsmbus2.Init.AddressingMode = SMBUS_ADDRESSINGMODE_7BIT;
  hsmbus2.Init.DualAddressMode = SMBUS_DUALADDRESS_DISABLE;
  hsmbus2.Init.OwnAddress2 = 0;
  hsmbus2.Init.OwnAddress2Masks = SMBUS_OA2_NOMASK;
  hsmbus2.Init.GeneralCallMode = SMBUS_GENERALCALL_DISABLE;
  hsmbus2.Init.NoStretchMode = SMBUS_NOSTRETCH_DISABLE;
  hsmbus2.Init.PacketErrorCheckMode = SMBUS_PEC_DISABLE;
  hsmbus2.Init.PeripheralMode = SMBUS_PERIPHERAL_MODE_SMBUS_SLAVE;
  hsmbus2.Init.SMBusTimeout = 0x00008186;
  if (HAL_SMBUS_Init(&hsmbus2) != HAL_OK) {
    Error_Handler();
  }

  /** configuration Alert Mode
   */
  if (HAL_SMBUS_EnableAlert_IT(&hsmbus2) != HAL_OK) {
    Error_Handler();
  }
}

static void MX_LPUART1_UART_Init(void) {

  hlpuart1.Instance = LPUART1;
  hlpuart1.Init.BaudRate = 115200;
  hlpuart1.Init.WordLength = UART_WORDLENGTH_8B;
  hlpuart1.Init.StopBits = UART_STOPBITS_1;
  hlpuart1.Init.Parity = UART_PARITY_NONE;
  hlpuart1.Init.Mode = UART_MODE_TX_RX;
  hlpuart1.Init.HwFlowCtl = UART_HWCONTROL_NONE;
  hlpuart1.Init.OneBitSampling = UART_ONE_BIT_SAMPLE_DISABLE;
  hlpuart1.Init.ClockPrescaler = UART_PRESCALER_DIV1;
  hlpuart1.AdvancedInit.AdvFeatureInit = UART_ADVFEATURE_NO_INIT;
  hlpuart1.FifoMode = UART_FIFOMODE_DISABLE;
  if (HAL_UART_Init(&hlpuart1) != HAL_OK) {
    Error_Handler();
  }
  if (HAL_UARTEx_SetTxFifoThreshold(&hlpuart1, UART_TXFIFO_THRESHOLD_1_8) !=
      HAL_OK) {
    Error_Handler();
  }
  if (HAL_UARTEx_SetRxFifoThreshold(&hlpuart1, UART_RXFIFO_THRESHOLD_1_8) !=
      HAL_OK) {
    Error_Handler();
  }
  if (HAL_UARTEx_DisableFifoMode(&hlpuart1) != HAL_OK) {
    Error_Handler();
  }
}

static void MX_USART2_UART_Init(void) {

  huart2.Instance = USART2;
  huart2.Init.BaudRate = 115200;
  huart2.Init.WordLength = UART_WORDLENGTH_8B;
  huart2.Init.StopBits = UART_STOPBITS_1;
  huart2.Init.Parity = UART_PARITY_NONE;
  huart2.Init.Mode = UART_MODE_TX_RX;
  huart2.Init.HwFlowCtl = UART_HWCONTROL_RTS_CTS;
  huart2.Init.OverSampling = UART_OVERSAMPLING_16;
  huart2.Init.OneBitSampling = UART_ONE_BIT_SAMPLE_DISABLE;
  huart2.Init.ClockPrescaler = UART_PRESCALER_DIV1;
  huart2.AdvancedInit.AdvFeatureInit = UART_ADVFEATURE_NO_INIT;
  if (HAL_UART_Init(&huart2) != HAL_OK) {
    Error_Handler();
  }
  if (HAL_UARTEx_SetTxFifoThreshold(&huart2, UART_TXFIFO_THRESHOLD_1_8) !=
      HAL_OK) {
    Error_Handler();
  }
  if (HAL_UARTEx_SetRxFifoThreshold(&huart2, UART_RXFIFO_THRESHOLD_1_8) !=
      HAL_OK) {
    Error_Handler();
  }
  if (HAL_UARTEx_DisableFifoMode(&huart2) != HAL_OK) {
    Error_Handler();
  }
}

static void MX_USART3_UART_Init(void) {

  huart3.Instance = USART3;
  huart3.Init.BaudRate = 115200;
  huart3.Init.WordLength = UART_WORDLENGTH_8B;
  huart3.Init.StopBits = UART_STOPBITS_1;
  huart3.Init.Parity = UART_PARITY_NONE;
  huart3.Init.Mode = UART_MODE_TX_RX;
  huart3.Init.HwFlowCtl = UART_HWCONTROL_NONE;
  huart3.Init.OverSampling = UART_OVERSAMPLING_16;
  huart3.Init.OneBitSampling = UART_ONE_BIT_SAMPLE_DISABLE;
  huart3.Init.ClockPrescaler = UART_PRESCALER_DIV1;
  huart3.AdvancedInit.AdvFeatureInit = UART_ADVFEATURE_NO_INIT;
  if (HAL_UART_Init(&huart3) != HAL_OK) {
    Error_Handler();
  }
  if (HAL_UARTEx_SetTxFifoThreshold(&huart3, UART_TXFIFO_THRESHOLD_1_8) !=
      HAL_OK) {
    Error_Handler();
  }
  if (HAL_UARTEx_SetRxFifoThreshold(&huart3, UART_RXFIFO_THRESHOLD_1_8) !=
      HAL_OK) {
    Error_Handler();
  }
  if (HAL_UARTEx_DisableFifoMode(&huart3) != HAL_OK) {
    Error_Handler();
  }
}

static void MX_SAI1_Init(void) {

  hsai_BlockB1.Instance = SAI1_Block_B;
  hsai_BlockB1.Init.Protocol = SAI_FREE_PROTOCOL;
  hsai_BlockB1.Init.AudioMode = SAI_MODEMASTER_TX;
  hsai_BlockB1.Init.DataSize = SAI_DATASIZE_8;
  hsai_BlockB1.Init.FirstBit = SAI_FIRSTBIT_MSB;
  hsai_BlockB1.Init.ClockStrobing = SAI_CLOCKSTROBING_FALLINGEDGE;
  hsai_BlockB1.Init.Synchro = SAI_ASYNCHRONOUS;
  hsai_BlockB1.Init.OutputDrive = SAI_OUTPUTDRIVE_DISABLE;
  hsai_BlockB1.Init.NoDivider = SAI_MASTERDIVIDER_ENABLE;
  hsai_BlockB1.Init.MckOverSampling = SAI_MCK_OVERSAMPLING_DISABLE;
  hsai_BlockB1.Init.FIFOThreshold = SAI_FIFOTHRESHOLD_EMPTY;
  hsai_BlockB1.Init.AudioFrequency = SAI_AUDIO_FREQUENCY_192K;
  hsai_BlockB1.Init.SynchroExt = SAI_SYNCEXT_DISABLE;
  hsai_BlockB1.Init.MonoStereoMode = SAI_STEREOMODE;
  hsai_BlockB1.Init.CompandingMode = SAI_NOCOMPANDING;
  hsai_BlockB1.Init.TriState = SAI_OUTPUT_NOTRELEASED;
  hsai_BlockB1.Init.PdmInit.Activation = DISABLE;
  hsai_BlockB1.Init.PdmInit.MicPairsNbr = 0;
  hsai_BlockB1.Init.PdmInit.ClockEnable = SAI_PDM_CLOCK1_ENABLE;
  hsai_BlockB1.FrameInit.FrameLength = 8;
  hsai_BlockB1.FrameInit.ActiveFrameLength = 1;
  hsai_BlockB1.FrameInit.FSDefinition = SAI_FS_STARTFRAME;
  hsai_BlockB1.FrameInit.FSPolarity = SAI_FS_ACTIVE_LOW;
  hsai_BlockB1.FrameInit.FSOffset = SAI_FS_FIRSTBIT;
  hsai_BlockB1.SlotInit.FirstBitOffset = 0;
  hsai_BlockB1.SlotInit.SlotSize = SAI_SLOTSIZE_DATASIZE;
  hsai_BlockB1.SlotInit.SlotNumber = 1;
  hsai_BlockB1.SlotInit.SlotActive = 0x00000000;
  if (HAL_SAI_Init(&hsai_BlockB1) != HAL_OK) {
    Error_Handler();
  }
  hsai_BlockA1.Instance = SAI1_Block_A;
  hsai_BlockA1.Init.AudioMode = SAI_MODEMASTER_TX;
  hsai_BlockA1.Init.Synchro = SAI_ASYNCHRONOUS;
  hsai_BlockA1.Init.OutputDrive = SAI_OUTPUTDRIVE_DISABLE;
  hsai_BlockA1.Init.NoDivider = SAI_MASTERDIVIDER_ENABLE;
  hsai_BlockA1.Init.FIFOThreshold = SAI_FIFOTHRESHOLD_EMPTY;
  hsai_BlockA1.Init.AudioFrequency = SAI_AUDIO_FREQUENCY_192K;
  hsai_BlockA1.Init.SynchroExt = SAI_SYNCEXT_DISABLE;
  hsai_BlockA1.Init.MonoStereoMode = SAI_STEREOMODE;
  hsai_BlockA1.Init.CompandingMode = SAI_NOCOMPANDING;
  hsai_BlockA1.Init.TriState = SAI_OUTPUT_NOTRELEASED;
  if (HAL_SAI_InitProtocol(&hsai_BlockA1, SAI_I2S_STANDARD,
                           SAI_PROTOCOL_DATASIZE_16BIT, 2) != HAL_OK) {
    Error_Handler();
  }
}

static void MX_SAI2_Init(void) {

  hsai_BlockA2.Instance = SAI2_Block_A;
  hsai_BlockA2.Init.Protocol = SAI_FREE_PROTOCOL;
  hsai_BlockA2.Init.AudioMode = SAI_MODEMASTER_TX;
  hsai_BlockA2.Init.DataSize = SAI_DATASIZE_8;
  hsai_BlockA2.Init.FirstBit = SAI_FIRSTBIT_MSB;
  hsai_BlockA2.Init.ClockStrobing = SAI_CLOCKSTROBING_FALLINGEDGE;
  hsai_BlockA2.Init.Synchro = SAI_ASYNCHRONOUS;
  hsai_BlockA2.Init.OutputDrive = SAI_OUTPUTDRIVE_DISABLE;
  hsai_BlockA2.Init.NoDivider = SAI_MASTERDIVIDER_ENABLE;
  hsai_BlockA2.Init.MckOverSampling = SAI_MCK_OVERSAMPLING_DISABLE;
  hsai_BlockA2.Init.FIFOThreshold = SAI_FIFOTHRESHOLD_EMPTY;
  hsai_BlockA2.Init.AudioFrequency = SAI_AUDIO_FREQUENCY_192K;
  hsai_BlockA2.Init.SynchroExt = SAI_SYNCEXT_DISABLE;
  hsai_BlockA2.Init.MonoStereoMode = SAI_STEREOMODE;
  hsai_BlockA2.Init.CompandingMode = SAI_NOCOMPANDING;
  hsai_BlockA2.Init.TriState = SAI_OUTPUT_NOTRELEASED;
  hsai_BlockA2.Init.PdmInit.Activation = DISABLE;
  hsai_BlockA2.Init.PdmInit.MicPairsNbr = 0;
  hsai_BlockA2.Init.PdmInit.ClockEnable = SAI_PDM_CLOCK1_ENABLE;
  hsai_BlockA2.FrameInit.FrameLength = 8;
  hsai_BlockA2.FrameInit.ActiveFrameLength = 1;
  hsai_BlockA2.FrameInit.FSDefinition = SAI_FS_STARTFRAME;
  hsai_BlockA2.FrameInit.FSPolarity = SAI_FS_ACTIVE_LOW;
  hsai_BlockA2.FrameInit.FSOffset = SAI_FS_FIRSTBIT;
  hsai_BlockA2.SlotInit.FirstBitOffset = 0;
  hsai_BlockA2.SlotInit.SlotSize = SAI_SLOTSIZE_DATASIZE;
  hsai_BlockA2.SlotInit.SlotNumber = 1;
  hsai_BlockA2.SlotInit.SlotActive = 0x00000000;
  if (HAL_SAI_Init(&hsai_BlockA2) != HAL_OK) {
    Error_Handler();
  }
}

static void MX_SPI3_Init(void) {

  /* SPI3 parameter configuration*/
  hspi3.Instance = SPI3;
  hspi3.Init.Mode = SPI_MODE_MASTER;
  hspi3.Init.Direction = SPI_DIRECTION_2LINES;
  hspi3.Init.DataSize = SPI_DATASIZE_8BIT;
  hspi3.Init.CLKPolarity = SPI_POLARITY_LOW;
  hspi3.Init.CLKPhase = SPI_PHASE_1EDGE;
  hspi3.Init.NSS = SPI_NSS_SOFT;
  hspi3.Init.BaudRatePrescaler = SPI_BAUDRATEPRESCALER_2;
  hspi3.Init.FirstBit = SPI_FIRSTBIT_MSB;
  hspi3.Init.TIMode = SPI_TIMODE_DISABLE;
  hspi3.Init.CRCCalculation = SPI_CRCCALCULATION_DISABLE;
  hspi3.Init.CRCPolynomial = 7;
  hspi3.Init.CRCLength = SPI_CRC_LENGTH_DATASIZE;
  hspi3.Init.NSSPMode = SPI_NSS_PULSE_ENABLE;
  if (HAL_SPI_Init(&hspi3) != HAL_OK) {
    Error_Handler();
  }
}

static void MX_TIM1_Init(void) {

  TIM_MasterConfigTypeDef sMasterConfig = {0};
  TIMEx_BreakInputConfigTypeDef sBreakInputConfig = {0};
  TIM_OC_InitTypeDef sConfigOC = {0};
  TIM_BreakDeadTimeConfigTypeDef sBreakDeadTimeConfig = {0};

  htim1.Instance = TIM1;
  htim1.Init.Prescaler = 0;
  htim1.Init.CounterMode = TIM_COUNTERMODE_UP;
  htim1.Init.Period = 65535;
  htim1.Init.ClockDivision = TIM_CLOCKDIVISION_DIV1;
  htim1.Init.RepetitionCounter = 0;
  htim1.Init.AutoReloadPreload = TIM_AUTORELOAD_PRELOAD_DISABLE;
  if (HAL_TIM_PWM_Init(&htim1) != HAL_OK) {
    Error_Handler();
  }
  sMasterConfig.MasterOutputTrigger = TIM_TRGO_RESET;
  sMasterConfig.MasterOutputTrigger2 = TIM_TRGO2_RESET;
  sMasterConfig.MasterSlaveMode = TIM_MASTERSLAVEMODE_DISABLE;
  if (HAL_TIMEx_MasterConfigSynchronization(&htim1, &sMasterConfig) != HAL_OK) {
    Error_Handler();
  }
  sBreakInputConfig.Source = TIM_BREAKINPUTSOURCE_BKIN;
  sBreakInputConfig.Enable = TIM_BREAKINPUTSOURCE_ENABLE;
  sBreakInputConfig.Polarity = TIM_BREAKINPUTSOURCE_POLARITY_HIGH;
  if (HAL_TIMEx_ConfigBreakInput(&htim1, TIM_BREAKINPUT_BRK,
                                 &sBreakInputConfig) != HAL_OK) {
    Error_Handler();
  }
  if (HAL_TIMEx_ConfigBreakInput(&htim1, TIM_BREAKINPUT_BRK2,
                                 &sBreakInputConfig) != HAL_OK) {
    Error_Handler();
  }
  sConfigOC.OCMode = TIM_OCMODE_PWM1;
  sConfigOC.Pulse = 0;
  sConfigOC.OCPolarity = TIM_OCPOLARITY_HIGH;
  sConfigOC.OCNPolarity = TIM_OCNPOLARITY_HIGH;
  sConfigOC.OCFastMode = TIM_OCFAST_DISABLE;
  sConfigOC.OCIdleState = TIM_OCIDLESTATE_RESET;
  sConfigOC.OCNIdleState = TIM_OCNIDLESTATE_RESET;
  if (HAL_TIM_PWM_ConfigChannel(&htim1, &sConfigOC, TIM_CHANNEL_3) != HAL_OK) {
    Error_Handler();
  }
  sBreakDeadTimeConfig.OffStateRunMode = TIM_OSSR_ENABLE;
  sBreakDeadTimeConfig.OffStateIDLEMode = TIM_OSSI_ENABLE;
  sBreakDeadTimeConfig.LockLevel = TIM_LOCKLEVEL_OFF;
  sBreakDeadTimeConfig.DeadTime = 0;
  sBreakDeadTimeConfig.BreakState = TIM_BREAK_ENABLE;
  sBreakDeadTimeConfig.BreakPolarity = TIM_BREAKPOLARITY_HIGH;
  sBreakDeadTimeConfig.BreakFilter = 0;
  sBreakDeadTimeConfig.Break2State = TIM_BREAK2_ENABLE;
  sBreakDeadTimeConfig.Break2Polarity = TIM_BREAK2POLARITY_HIGH;
  sBreakDeadTimeConfig.Break2Filter = 0;
  sBreakDeadTimeConfig.AutomaticOutput = TIM_AUTOMATICOUTPUT_DISABLE;
  if (HAL_TIMEx_ConfigBreakDeadTime(&htim1, &sBreakDeadTimeConfig) != HAL_OK) {
    Error_Handler();
  }
  HAL_TIM_MspPostInit(&htim1);
}

static void MX_TIM2_Init(void) {

  TIM_MasterConfigTypeDef sMasterConfig = {0};
  TIM_OC_InitTypeDef sConfigOC = {0};

  htim2.Instance = TIM2;
  htim2.Init.Prescaler = 0;
  htim2.Init.CounterMode = TIM_COUNTERMODE_UP;
  htim2.Init.Period = 4294967295;
  htim2.Init.ClockDivision = TIM_CLOCKDIVISION_DIV1;
  htim2.Init.AutoReloadPreload = TIM_AUTORELOAD_PRELOAD_DISABLE;
  if (HAL_TIM_PWM_Init(&htim2) != HAL_OK) {
    Error_Handler();
  }
  sMasterConfig.MasterOutputTrigger = TIM_TRGO_RESET;
  sMasterConfig.MasterSlaveMode = TIM_MASTERSLAVEMODE_DISABLE;
  if (HAL_TIMEx_MasterConfigSynchronization(&htim2, &sMasterConfig) != HAL_OK) {
    Error_Handler();
  }
  sConfigOC.OCMode = TIM_OCMODE_PWM1;
  sConfigOC.Pulse = 0;
  sConfigOC.OCPolarity = TIM_OCPOLARITY_HIGH;
  sConfigOC.OCFastMode = TIM_OCFAST_DISABLE;
  if (HAL_TIM_PWM_ConfigChannel(&htim2, &sConfigOC, TIM_CHANNEL_1) != HAL_OK) {
    Error_Handler();
  }
  if (HAL_TIM_PWM_ConfigChannel(&htim2, &sConfigOC, TIM_CHANNEL_3) != HAL_OK) {
    Error_Handler();
  }
  HAL_TIM_MspPostInit(&htim2);
}

static void MX_TIM3_Init(void) {

  TIM_MasterConfigTypeDef sMasterConfig = {0};
  TIM_OC_InitTypeDef sConfigOC = {0};

  htim3.Instance = TIM3;
  htim3.Init.Prescaler = 0;
  htim3.Init.CounterMode = TIM_COUNTERMODE_UP;
  htim3.Init.Period = 65535;
  htim3.Init.ClockDivision = TIM_CLOCKDIVISION_DIV1;
  htim3.Init.AutoReloadPreload = TIM_AUTORELOAD_PRELOAD_DISABLE;
  if (HAL_TIM_PWM_Init(&htim3) != HAL_OK) {
    Error_Handler();
  }
  sMasterConfig.MasterOutputTrigger = TIM_TRGO_RESET;
  sMasterConfig.MasterSlaveMode = TIM_MASTERSLAVEMODE_DISABLE;
  if (HAL_TIMEx_MasterConfigSynchronization(&htim3, &sMasterConfig) != HAL_OK) {
    Error_Handler();
  }
  sConfigOC.OCMode = TIM_OCMODE_PWM1;
  sConfigOC.Pulse = 0;
  sConfigOC.OCPolarity = TIM_OCPOLARITY_HIGH;
  sConfigOC.OCFastMode = TIM_OCFAST_DISABLE;
  if (HAL_TIM_PWM_ConfigChannel(&htim3, &sConfigOC, TIM_CHANNEL_2) != HAL_OK) {
    Error_Handler();
  }
  if (HAL_TIM_PWM_ConfigChannel(&htim3, &sConfigOC, TIM_CHANNEL_3) != HAL_OK) {
    Error_Handler();
  }
  HAL_TIM_MspPostInit(&htim3);
}

static void MX_TIM4_Init(void) {

  TIM_MasterConfigTypeDef sMasterConfig = {0};
  TIM_OC_InitTypeDef sConfigOC = {0};

  htim4.Instance = TIM4;
  htim4.Init.Prescaler = 0;
  htim4.Init.CounterMode = TIM_COUNTERMODE_UP;
  htim4.Init.Period = 65535;
  htim4.Init.ClockDivision = TIM_CLOCKDIVISION_DIV1;
  htim4.Init.AutoReloadPreload = TIM_AUTORELOAD_PRELOAD_DISABLE;
  if (HAL_TIM_PWM_Init(&htim4) != HAL_OK) {
    Error_Handler();
  }
  sMasterConfig.MasterOutputTrigger = TIM_TRGO_RESET;
  sMasterConfig.MasterSlaveMode = TIM_MASTERSLAVEMODE_DISABLE;
  if (HAL_TIMEx_MasterConfigSynchronization(&htim4, &sMasterConfig) != HAL_OK) {
    Error_Handler();
  }
  sConfigOC.OCMode = TIM_OCMODE_PWM1;
  sConfigOC.Pulse = 0;
  sConfigOC.OCPolarity = TIM_OCPOLARITY_HIGH;
  sConfigOC.OCFastMode = TIM_OCFAST_DISABLE;
  if (HAL_TIM_PWM_ConfigChannel(&htim4, &sConfigOC, TIM_CHANNEL_4) != HAL_OK) {
    Error_Handler();
  }
  HAL_TIM_MspPostInit(&htim4);
}

static void MX_TIM15_Init(void) {

  TIM_MasterConfigTypeDef sMasterConfig = {0};
  TIM_OC_InitTypeDef sConfigOC = {0};
  TIM_BreakDeadTimeConfigTypeDef sBreakDeadTimeConfig = {0};

  htim15.Instance = TIM15;
  htim15.Init.Prescaler = 0;
  htim15.Init.CounterMode = TIM_COUNTERMODE_UP;
  htim15.Init.Period = 65535;
  htim15.Init.ClockDivision = TIM_CLOCKDIVISION_DIV1;
  htim15.Init.RepetitionCounter = 0;
  htim15.Init.AutoReloadPreload = TIM_AUTORELOAD_PRELOAD_DISABLE;
  if (HAL_TIM_PWM_Init(&htim15) != HAL_OK) {
    Error_Handler();
  }
  sMasterConfig.MasterOutputTrigger = TIM_TRGO_RESET;
  sMasterConfig.MasterSlaveMode = TIM_MASTERSLAVEMODE_DISABLE;
  if (HAL_TIMEx_MasterConfigSynchronization(&htim15, &sMasterConfig) !=
      HAL_OK) {
    Error_Handler();
  }
  sConfigOC.OCMode = TIM_OCMODE_PWM1;
  sConfigOC.Pulse = 0;
  sConfigOC.OCPolarity = TIM_OCPOLARITY_HIGH;
  sConfigOC.OCNPolarity = TIM_OCNPOLARITY_HIGH;
  sConfigOC.OCFastMode = TIM_OCFAST_DISABLE;
  sConfigOC.OCIdleState = TIM_OCIDLESTATE_RESET;
  sConfigOC.OCNIdleState = TIM_OCNIDLESTATE_RESET;
  if (HAL_TIM_PWM_ConfigChannel(&htim15, &sConfigOC, TIM_CHANNEL_1) != HAL_OK) {
    Error_Handler();
  }
  sBreakDeadTimeConfig.OffStateRunMode = TIM_OSSR_DISABLE;
  sBreakDeadTimeConfig.OffStateIDLEMode = TIM_OSSI_DISABLE;
  sBreakDeadTimeConfig.LockLevel = TIM_LOCKLEVEL_OFF;
  sBreakDeadTimeConfig.DeadTime = 0;
  sBreakDeadTimeConfig.BreakState = TIM_BREAK_DISABLE;
  sBreakDeadTimeConfig.BreakPolarity = TIM_BREAKPOLARITY_HIGH;
  sBreakDeadTimeConfig.AutomaticOutput = TIM_AUTOMATICOUTPUT_DISABLE;
  if (HAL_TIMEx_ConfigBreakDeadTime(&htim15, &sBreakDeadTimeConfig) != HAL_OK) {
    Error_Handler();
  }
  HAL_TIM_MspPostInit(&htim15);
}

static void MX_USB_OTG_FS_USB_Init(void) {

}

static void MX_GPIO_Init(void) {
  GPIO_InitTypeDef GPIO_InitStruct = {0};

  /* GPIO Ports Clock Enable */
  __HAL_RCC_GPIOE_CLK_ENABLE();
  __HAL_RCC_GPIOC_CLK_ENABLE();
  __HAL_RCC_GPIOF_CLK_ENABLE();
  __HAL_RCC_GPIOH_CLK_ENABLE();
  __HAL_RCC_GPIOA_CLK_ENABLE();
  __HAL_RCC_GPIOB_CLK_ENABLE();
  __HAL_RCC_GPIOD_CLK_ENABLE();
  __HAL_RCC_GPIOG_CLK_ENABLE();
  HAL_PWREx_EnableVddIO2();

  /*Configure GPIO pin Output Level */
  HAL_GPIO_WritePin(GPIOF, GPIO_PIN_13 | GPIO_PIN_14, GPIO_PIN_RESET);

  /*Configure GPIO pin Output Level */
  HAL_GPIO_WritePin(
      GPIOE, GPIO_PIN_7 | GPIO_PIN_8 | GPIO_PIN_9 | GPIO_PIN_10 | GPIO_PIN_11,
      GPIO_PIN_RESET);

  /*Configure GPIO pin : PA4 */
  GPIO_InitStruct.Pin = GPIO_PIN_4;
  GPIO_InitStruct.Mode = GPIO_MODE_AF_PP;
  GPIO_InitStruct.Pull = GPIO_NOPULL;
  GPIO_InitStruct.Speed = GPIO_SPEED_FREQ_VERY_HIGH;
  GPIO_InitStruct.Alternate = GPIO_AF5_SPI1;
  HAL_GPIO_Init(GPIOA, &GPIO_InitStruct);

  /*Configure GPIO pins : PA5 PA6 PA7 */
  GPIO_InitStruct.Pin = GPIO_PIN_5 | GPIO_PIN_6 | GPIO_PIN_7;
  GPIO_InitStruct.Mode = GPIO_MODE_INPUT;
  GPIO_InitStruct.Pull = GPIO_PULLUP;
  HAL_GPIO_Init(GPIOA, &GPIO_InitStruct);

  /*Configure GPIO pins : PF13 PF14 */
  GPIO_InitStruct.Pin = GPIO_PIN_13 | GPIO_PIN_14;
  GPIO_InitStruct.Mode = GPIO_MODE_OUTPUT_OD;
  GPIO_InitStruct.Pull = GPIO_NOPULL;
  GPIO_InitStruct.Speed = GPIO_SPEED_FREQ_LOW;
  HAL_GPIO_Init(GPIOF, &GPIO_InitStruct);

  /*Configure GPIO pins : PE7 PE8 PE10 */
  GPIO_InitStruct.Pin = GPIO_PIN_7 | GPIO_PIN_8 | GPIO_PIN_10;
  GPIO_InitStruct.Mode = GPIO_MODE_OUTPUT_PP;
  GPIO_InitStruct.Pull = GPIO_PULLUP;
  GPIO_InitStruct.Speed = GPIO_SPEED_FREQ_LOW;
  HAL_GPIO_Init(GPIOE, &GPIO_InitStruct);

  /*Configure GPIO pins : PE9 PE11 */
  GPIO_InitStruct.Pin = GPIO_PIN_9 | GPIO_PIN_11;
  GPIO_InitStruct.Mode = GPIO_MODE_OUTPUT_OD;
  GPIO_InitStruct.Pull = GPIO_NOPULL;
  GPIO_InitStruct.Speed = GPIO_SPEED_FREQ_LOW;
  HAL_GPIO_Init(GPIOE, &GPIO_InitStruct);

  /*Configure GPIO pin : PD14 */
  GPIO_InitStruct.Pin = GPIO_PIN_14;
  GPIO_InitStruct.Mode = GPIO_MODE_INPUT;
  GPIO_InitStruct.Pull = GPIO_PULLUP;
  HAL_GPIO_Init(GPIOD, &GPIO_InitStruct);

  /*Configure GPIO pins : PC8 PC9 */
  GPIO_InitStruct.Pin = GPIO_PIN_8 | GPIO_PIN_9;
  GPIO_InitStruct.Mode = GPIO_MODE_AF_PP;
  GPIO_InitStruct.Pull = GPIO_NOPULL;
  GPIO_InitStruct.Speed = GPIO_SPEED_FREQ_VERY_HIGH;
  GPIO_InitStruct.Alternate = GPIO_AF12_SDMMC1;
  HAL_GPIO_Init(GPIOC, &GPIO_InitStruct);

  /*Configure GPIO pins : PA8 PA10 PA11 PA12 */
  GPIO_InitStruct.Pin = GPIO_PIN_8 | GPIO_PIN_10 | GPIO_PIN_11 | GPIO_PIN_12;
  GPIO_InitStruct.Mode = GPIO_MODE_AF_PP;
  GPIO_InitStruct.Pull = GPIO_NOPULL;
  GPIO_InitStruct.Speed = GPIO_SPEED_FREQ_VERY_HIGH;
  GPIO_InitStruct.Alternate = GPIO_AF10_OTG_FS;
  HAL_GPIO_Init(GPIOA, &GPIO_InitStruct);

  /*Configure GPIO pin : PA9 */
  GPIO_InitStruct.Pin = GPIO_PIN_9;
  GPIO_InitStruct.Mode = GPIO_MODE_INPUT;
  GPIO_InitStruct.Pull = GPIO_NOPULL;
  HAL_GPIO_Init(GPIOA, &GPIO_InitStruct);

  /*Configure GPIO pin : PD2 */
  GPIO_InitStruct.Pin = GPIO_PIN_2;
  GPIO_InitStruct.Mode = GPIO_MODE_AF_PP;
  GPIO_InitStruct.Pull = GPIO_NOPULL;
  GPIO_InitStruct.Speed = GPIO_SPEED_FREQ_VERY_HIGH;
  GPIO_InitStruct.Alternate = GPIO_AF12_SDMMC1;
  HAL_GPIO_Init(GPIOD, &GPIO_InitStruct);

}

/* USER CODE BEGIN 4 */
#ifdef __GNUC__
#define PUTCHAR_PROTOTYPE int __io_putchar(int ch)
#else
#define PUTCHAR_PROTOTYPE int fputc(int ch, FILE *f)
#endif /* __GNUC__ */
PUTCHAR_PROTOTYPE {
  HAL_UART_Transmit(&hlpuart1, (uint8_t *)&ch, 1, 0xFFFF);
  return ch;
}

/* USER CODE END 4 */

void Error_Handler(void) {
  __disable_irq();
  while (1) {
  }
}

#ifdef USE_FULL_ASSERT
/**
 * @brief  Reports the name of the source file and the source line number
 *         where the assert_param error has occurred.
 * @param  file: pointer to the source file name
 * @param  line: assert_param error line source number
 * @retval None
 */
void assert_failed(uint8_t *file, uint32_t line) {
  /* USER CODE BEGIN 6 */
  /* User can add his own implementation to report the file name and line
     number, ex: printf("Wrong parameters value: file %s on line %d\r\n", file,
     line) */
  /* USER CODE END 6 */
}
#endif /* USE_FULL_ASSERT */
